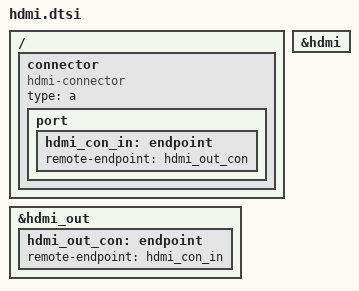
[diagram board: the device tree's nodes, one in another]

/ {
	connector {
		compatible = "hdmi-connector";
		type = "a";

		port {
			hdmi_con_in: endpoint {
				remote-endpoint = <&hdmi_out_con>;
			};
		};
	};
};

&hdmi {
	status = "okay";
};

&hdmi_out {
	hdmi_out_con: endpoint {
		remote-endpoint = <&hdmi_con_in>;
	};
};

